# R7FA0E303 register map
Vendor: Renesas Electronics Corporation; Series: RA0; File version: 1.00.00
CPU: CM23 r1p0, little endian, no MPU, no FPU, VTOR, 2 interrupt priority bits, 64 interrupts
Registers are 16-bit, read-write, reset 0x0 unless marked. A register's access mark holds for its fields unless they carry their own. Offsets are from the block's base; [hi:lo] are bit positions; {n}, {i} and the like mark numbered series; <NAME> marks a mode.

## PORT3 — Port 3 Control
Base 0x400A0060
0x00 PODR3 — Port 3 Output Data Register
  [0] PODR00 — P300 Output Data
    0=Low output; 1=High output
0x02 PDR3 — Port 3 Direction Register
  [0] PDR00 — P300 Direction
    0=Output 0; 1=Output 1
0x06 PIDR3 ro (reset mask 0xFFFE) — Port 3 State Register
  [0] PIDR00 — P300 State
    0=Low level; 1=High level
0x08 PORR3 wo — Port 3 Output Reset Register
  [0] PORR00 — P300 Output Reset
    0=No effect on output; 1=Low output
0x0A POSR3 wo — Port 3 Output Set Register
  [0] POSR00 — P300 Output Set
    0=No effect on output; 1=High output

## PORGA — Product Organize
Base 0x400A1000
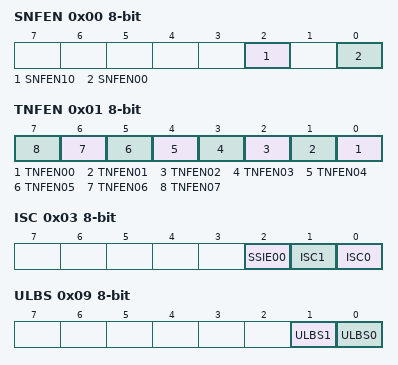
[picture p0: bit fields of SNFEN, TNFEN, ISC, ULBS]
0x00 SNFEN 8-bit — SAU Noise Filter Enable Register
  [2] SNFEN10 — Use of Noise Filter of RXD1 Pin
    0=Noise filter OFF; 1=Noise filter ON
  [0] SNFEN00 — Use of Noise Filter of RXD0 Pin
    0=Noise filter OFF; 1=Noise filter ON
0x01 TNFEN 8-bit — TAU Noise Filter Enable Register
  [all] fields
    0=Turns the noise filter off; 1=Turns the noise filter on
  [n] TNFEN{n:02} (n=0..7) — Enabling or Disabling Use of the Noise Filter for the TI{n:02} Pin
0x03 ISC 8-bit — Input Switch Control Register
  [2] SSIE00 — Setting of the SSI00 Input of Channel 0 in the Communications Through SPI00 in the Slave Mode
    0=The SSI00 input is disabled; 1=The SSI00 input is enabled
  [1] ISC1 — Switching Channel 7 Input of Timer Array Unit
    0=Uses the input signal of the TI07 pin as a timer input (normal operation); 1=Input signal of the RXD0 pin is used as timer input (detects the wakeup signal and measures the low width of the break field and the pulse width of the sync field)
  [0] ISC0 — Switching External Interrupt (IRQ0) Input
    0=Uses the input signal of the IRQ0 pin as an external interrupt (normal operation); 1=Uses the input signal of the RXD0 pin as an external interrupt (wakeup signal detection)
0x04 TIS0 8-bit — Timer Input Select Register 0
  [2] TIS — Selection of Timer Input Used with Channel 5
    0=Input signal of timer input pin (TI05); 1=Low-speed on-chip oscillator (LOCO)
0x09 ULBS 8-bit — UART Loopback Select Register
  [1] ULBS1 — Selection of the UART1 Loopback Function
    0=Inputs the states of the RXD1 pin of serial array unit UART1 to the reception shift register; 1=Loops back output from the transmission shift register to the reception shift register
  [0] ULBS0 — Selection of the UART0 Loopback Function
    0=Inputs the states of the RXD0 pin of serial array unit UART0 to the reception shift register; 1=Loops back output from the transmission shift register to the reception shift register

## ADC_D — A/D Converter
Base 0x400A1800
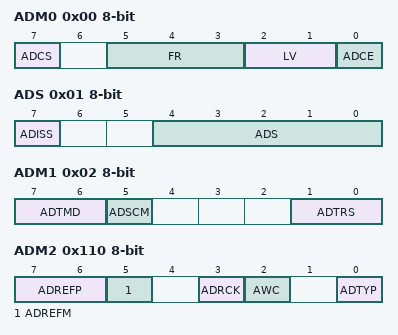
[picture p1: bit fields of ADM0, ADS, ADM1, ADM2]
0x00 ADM0 8-bit — A/D Converter Mode Register 0
  [7] ADCS — A/D conversion operation control
    0=Stops conversion operation [When read] Conversion is stopped or in standby; 1=Enables conversion operation [When read] While in the no wait mode (both software and hardware trigger mode): Conversion is enabled While in the wait mode (both software and hardware trigger mode): A/D power supply stabilization wait time + conversion
  [5:3] FR — Select Conversion Clock (fAD)
    0=PCLKB/64; 1=PCLKB/32; 2=PCLKB/16; 3=PCLKB/8; 4=PCLKB/6; 5=PCLKB/5; 6=PCLKB/4; 7=PCLKB/2
  [2:1] LV — Select Operation voltage mode
    0=Normal mode 1; 1=Normal mode 2; 2=Low voltage mode 1; 3=Low voltage mode 2
  [0] ADCE — A/D voltage comparator operation control
    0=Stops A/D voltage comparator operation; 1=Enables A/D voltage comparator operation
0x01 ADS 8-bit — Analog Input Channel Specification Register
  [7] ADISS — Select Internal or External of Analog Input (See .)
    0=External input; 1=Internal circuit input
  [4:0] ADS — Selection of the Analog Input Channel (See .)
0x02 ADM1 8-bit — A/D Converter Mode Register 1
  [7:6] ADTMD — Selection of the A/D Conversion Trigger Mode
    2=Hardware trigger no-wait mode; 3=Hardware trigger wait mode; 0b0x=Software trigger mode
  [5] ADSCM — Specification of the A/D Conversion Mode
    0=Sequential conversion mode; 1=One-shot conversion mode
  [1:0] ADTRS — Selection of the Hardware Trigger Signal
    0=Timer Array Unit channel 1 count or capture end interrupt signal (TAU0_TMI01); 3=32-bit interval timer interrupt signal (ADITL0 (= TML32_ITL0)); other=Others (Setting prohibited.)
0x06 ADCR ro — 10-bit A/D Conversion Result Register
0x07 ADCRH 8-bit ro — 8-bit A/D Conversion Result Register
0x110 ADM2 8-bit — A/D Converter Mode Register 2
  [7:6] ADREFP — Selection of the ‘+’ Side Reference Voltage Source of the A/D Converter
    0=Supplied from VCC; 1=Supplied from VREFH0/AN000; 2=Supplied from the internal reference voltage; 3=Setting prohibited
  [5] ADREFM — Selection of the ‘-’ Side Reference Voltage of the A/D Converter
    0=Supplied from VSS; 1=Supplied from VREFL0/AN001
  [3] ADRCK — Checking the Upper Limit and Lower Limit Conversion Result Values
    0=The interrupt signal (ADC10_ADI) is output when the ADLL register ≤ the ADCR register ≤ the ADUL register (AREA 1); 1=The interrupt signal (ADC10_ADI) is output when the ADCR register < the ADLL register (AREA 2) or the ADUL register < the ADCR register (AREA 3)
  [2] AWC — Specification of the Snooze Mode
    0=Do not use the Snooze mode function; 1=Use the Snooze mode function
  [0] ADTYP — Selection of the resolution
    0=10-bit resolution; 1=8-bit resolution; other=Others (Setting prohibited)
0x111 ADUL 8-bit reset 0xFF — Conversion Result Comparison Upper Limit Setting Register
0x112 ADLL 8-bit — Conversion Result Comparison Lower Limit Setting Register
0x113 ADTES 8-bit — A/D Test Register
  [1:0] ADTES — Selection of A/D Conversion Target for Testing
    0=ANxxx, temperature sensor output voltage or internal reference voltage (Set by analog input channel specification register (ADS)); 2=The ‘-’ side reference voltage (selected by the ADREFM bit of the ADM2 register); 3=The ‘+’ side reference voltage (selected by the ADREFP[1:0] bits of the ADM2 register); other=Others (Setting prohibited.)

## PCLBUZ — Clock Output/Buzzer Output Controller
Base 0x400A3B00
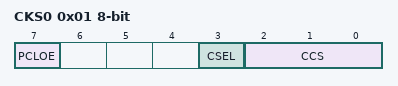
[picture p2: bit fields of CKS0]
0x01 CKS0 8-bit — Clock Out Control Register 0
  [7] PCLOE — Clock Out Enable
    0=Disable clock out; 1=Enable clock out
  [3] CSEL — Clock Out Select
    0=FMAIN; 1=FSUB
  [2:0] CCS — Clock Out Divide Select
    0=value after reset FMAIN (When CKS0.CSEL = 0) FSUB (When CKS0.CSEL = 1); 1=FMAIN × 1/2 (When CKS0.CSEL = 0) FSUB × 1/2 (When CKS0.CSEL = 1); 2=FMAIN × 1/22 (When CKS0.CSEL = 0) FSUB × 1/22 (When CKS0.CSEL = 1); 3=FMAIN × 1/23 (When CKS0.CSEL = 0) FSUB × 1/23 (When CKS0.CSEL = 1); 4=FMAIN × 1/24 (When CKS0.CSEL = 0) FSUB × 1/24 (When CKS0.CSEL = 1); 5=FMAIN × 1/211 (When CKS0.CSEL = 0) FSUB × 1/25 (When CKS0.CSEL = 1); 6=FMAIN 1/212 (When CKS0.CSEL = 0) FSUB × 1/26 (When CKS0.CSEL = 1); 7=FMAIN × 1/213 (When CKS0.CSEL = 0) FSUB × 1/27 (When CKS0.CSEL = 1)
